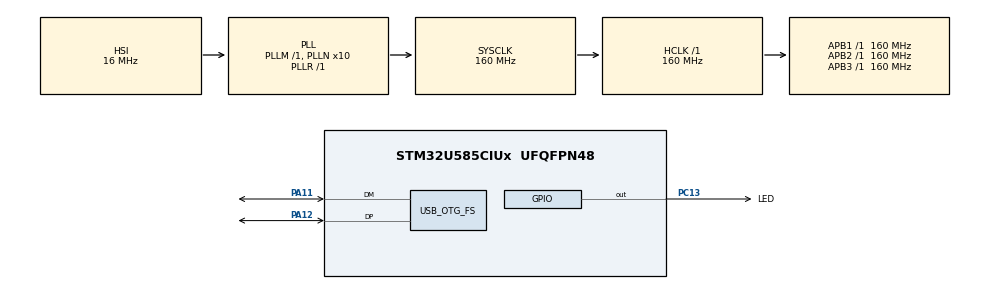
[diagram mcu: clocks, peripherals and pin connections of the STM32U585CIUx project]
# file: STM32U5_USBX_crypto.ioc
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CORTEX_M33_NS.userName=CORTEX_M33
Mcu.Family=STM32U5
Mcu.Name=STM32U585CIUx
Mcu.Package=UFQFPN48
NVIC.OTG_FS_IRQn=true\:7\:0\:true\:false\:true\:false\:true\:true\:true
NVIC.PriorityGroup=NVIC_PRIORITYGROUP_4
NVIC.TIM6_IRQn=true\:15\:0\:false\:false\:true\:false\:false\:true\:true
NVIC.TimeBase=TIM6_IRQn
NVIC.TimeBaseIP=TIM6
PA11.GPIO_Speed=GPIO_SPEED_FREQ_HIGH
PA11.Mode=Device_Only
PA11.Signal=USB_OTG_FS_DM
PA12.GPIO_Speed=GPIO_SPEED_FREQ_HIGH
PA12.Mode=Device_Only
PA12.Signal=USB_OTG_FS_DP
PC13.GPIO_Label=LED
PC13.Signal=GPIO_Output
PH0-OSC_IN\ (PH0).Mode=HSE-External-Oscillator
PH0-OSC_IN\ (PH0).Signal=RCC_OSC_IN
PH1-OSC_OUT\ (PH1).Mode=HSE-External-Oscillator
PH1-OSC_OUT\ (PH1).Signal=RCC_OSC_OUT
ProjectManager.HeapSize=0x200
ProjectManager.StackSize=0x400
ProjectManager.TargetToolchain=STM32CubeIDE
RCC.ADCFreq_Value=16000000
RCC.AHBFreq_Value=160000000
RCC.APB1Freq_Value=160000000
RCC.APB1TimFreq_Value=160000000
RCC.APB2Freq_Value=160000000
RCC.APB2TimFreq_Value=160000000
RCC.APB3Freq_Value=160000000
RCC.CortexFreq_Value=160000000
RCC.EPOD_VALUE=16000000
RCC.HCLKFreq_Value=160000000
RCC.HSE_VALUE=16000000
RCC.HSI48_VALUE=48000000
RCC.HSI_VALUE=16000000
RCC.LSE_VALUE=32768
RCC.LSIDIV_VALUE=32000
RCC.MSIClockRange=RCC_MSIRANGE_0
RCC.MSI_VALUE=48000000
RCC.PLL1R=1
RCC.PLLFRACN=0
RCC.PLLN=10
RCC.PLLSourceVirtual=RCC_PLLSOURCE_HSI
RCC.SYSCLKFreq_VALUE=160000000
RCC.SYSCLKSource=RCC_SYSCLKSOURCE_PLLCLK
RCC.USBFreq_Value=48000000
RCC.VCOOutputFreq_Value=160000000
USBX.BSP.number=1
USBX.Core_System=1
USBX.MAX_POWER_IN_MILLI_AMPER=0
USBX.USBD_CDCACM_EPINCMD_ADDR=2
USBX.USBD_CDCACM_EPIN_ADDR=1
USBX.USBD_SERIAL_NUMBER=CDC_ACM001
USBX.USBX_DEVICE_SYS_SIZE=4*1024
USBX.UX_DEVICE_APP_MEM_POOL_SIZE=8192
USBX.UX_DEVICE_CDC_ACM=1
USBX.UX_DEVICE_CLASS_CDC_ACM_WRITE_AUTO_ZLP=1
USBX.UX_Device_Controller=1
USBX.UX_Device_CoreStack=1
USBX.UX_SLAVE_REQUEST_DATA_MAX_LENGTH=512
USBX0.BSP.STBoard=false
USBX0.BSP.api=Unknown
USBX0.BSP.condition=SEMAOoUSBOoOTGOoFSOoDEVICEOoFOROoUSBX & \!DIE455
USBX0.BSP.instance=USB_OTG_FS
USBX0.BSP.ip=USB_OTG_FS
USBX0.BSP.mode=Device_Only
USBX0.BSP.name=USBDevice
USBX0.BSP.solution=USB_OTG_FS
USB_OTG_FS.VirtualMode=Device_Only
VP_CRC_VS_CRC.Mode=CRC_Activate
VP_ICACHE_VS_ENABLE_ICACHE_MEMORY.Mode=Memoryregions
VP_LPBAMQUEUE_VS_QUEUE.Mode=QUEUEMODE
VP_LPBAM_VS_SIG1.Mode=SmartRun
VP_LPBAM_VS_SIG4.Mode=LPDMA1
VP_MEMORYMAP_VS_MEMORYMAP.Mode=CurAppReg
VP_PKA_VS_PKA.Mode=PKA_Activate
VP_PWR_VS_SECSignals.Mode=Security/Privilege
VP_RNG_VS_RNG.Mode=RNG_Activate
VP_SYS_VS_tim6.Mode=TIM6
VP_THREADX_VS_RTOSJjThreadXJjCoreJjDefault.Mode=Core_Default
VP_USBX_Core_System.Mode=Core_System
VP_USBX_UX\ Device\ CDC\ ACM\ Class_FS.Mode=UX_Device_class_CDC_ACM_FS
VP_USBX_UX\ Device\ Controller_FS.Mode=UX_Device_Controller_FS
VP_USBX_UX\ Device\ CoreStack_FS.Mode=UX_Device_CoreStack_FS
board=custom

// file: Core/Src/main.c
/* USER CODE BEGIN Header */
/**
  ******************************************************************************
  * @file           : main.c
  * @brief          : Main program body
  ******************************************************************************
  * @attention
  *
  * Copyright (c) 2025 STMicroelectronics.
  * All rights reserved.
  *
  * This software is licensed under terms that can be found in the LICENSE file
  * in the root directory of this software component.
  * If no LICENSE file comes with this software, it is provided AS-IS.
  *
  ******************************************************************************
  */
/* USER CODE END Header */
#include "app_threadx.h"
#include "main.h"

CRC_HandleTypeDef hcrc;

PKA_HandleTypeDef hpka;

RNG_HandleTypeDef hrng;

PCD_HandleTypeDef hpcd_USB_OTG_FS;

void SystemClock_Config(void);
static void MX_GPIO_Init(void);
static void MX_ICACHE_Init(void);
static void MX_RNG_Init(void);
static void MX_PKA_Init(void);
static void MX_CRC_Init(void);
void read_uid(uint32_t uid[3]);

/* USER CODE BEGIN 0 */
 void my_debug_marker(int x) {
    //while(1) {

        for (int i = 0; i < x; i++)
           {
               HAL_GPIO_TogglePin(LED_GPIO_Port, LED_Pin);
               for (volatile int j = 0; j < 1000000; j++); // petit délai CPU busy
           }
        for (volatile long int j = 0; j < 10000000; j++);
    //}
}
/* USER CODE END 0 */

int main(void)
{

  /* MCU Configuration--------------------------------------------------------*/

  /* Reset of all peripherals, Initializes the Flash interface and the Systick. */
  HAL_Init();

  /* Configure the system clock */
  SystemClock_Config();

  /* Initialize all configured peripherals */
  MX_GPIO_Init();
  MX_ICACHE_Init();
  MX_RNG_Init();
  MX_PKA_Init();
  MX_CRC_Init();

  MX_ThreadX_Init();

  /* We should never get here as control is now taken by the scheduler */

  /* Infinite loop */
  while (1)
  {

  }
}

void SystemClock_Config(void)
{
  RCC_OscInitTypeDef RCC_OscInitStruct = {0};
  RCC_ClkInitTypeDef RCC_ClkInitStruct = {0};

  /** Configure the main internal regulator output voltage
  */
  if (HAL_PWREx_ControlVoltageScaling(PWR_REGULATOR_VOLTAGE_SCALE1) != HAL_OK)
  {
    Error_Handler();
  }

  /** Initializes the CPU, AHB and APB buses clocks
  */
  RCC_OscInitStruct.OscillatorType = RCC_OSCILLATORTYPE_HSI48|RCC_OSCILLATORTYPE_HSI;
  RCC_OscInitStruct.HSIState = RCC_HSI_ON;
  RCC_OscInitStruct.HSI48State = RCC_HSI48_ON;
  RCC_OscInitStruct.HSICalibrationValue = RCC_HSICALIBRATION_DEFAULT;
  RCC_OscInitStruct.PLL.PLLState = RCC_PLL_ON;
  RCC_OscInitStruct.PLL.PLLSource = RCC_PLLSOURCE_HSI;
  RCC_OscInitStruct.PLL.PLLMBOOST = RCC_PLLMBOOST_DIV1;
  RCC_OscInitStruct.PLL.PLLM = 1;
  RCC_OscInitStruct.PLL.PLLN = 10;
  RCC_OscInitStruct.PLL.PLLP = 2;
  RCC_OscInitStruct.PLL.PLLQ = 2;
  RCC_OscInitStruct.PLL.PLLR = 1;
  RCC_OscInitStruct.PLL.PLLRGE = RCC_PLLVCIRANGE_1;
  RCC_OscInitStruct.PLL.PLLFRACN = 0;
  if (HAL_RCC_OscConfig(&RCC_OscInitStruct) != HAL_OK)
  {
    Error_Handler();
  }

  /** Initializes the CPU, AHB and APB buses clocks
  */
  RCC_ClkInitStruct.ClockType = RCC_CLOCKTYPE_HCLK|RCC_CLOCKTYPE_SYSCLK
                              |RCC_CLOCKTYPE_PCLK1|RCC_CLOCKTYPE_PCLK2
                              |RCC_CLOCKTYPE_PCLK3;
  RCC_ClkInitStruct.SYSCLKSource = RCC_SYSCLKSOURCE_PLLCLK;
  RCC_ClkInitStruct.AHBCLKDivider = RCC_SYSCLK_DIV1;
  RCC_ClkInitStruct.APB1CLKDivider = RCC_HCLK_DIV1;
  RCC_ClkInitStruct.APB2CLKDivider = RCC_HCLK_DIV1;
  RCC_ClkInitStruct.APB3CLKDivider = RCC_HCLK_DIV1;

  if (HAL_RCC_ClockConfig(&RCC_ClkInitStruct, FLASH_LATENCY_4) != HAL_OK)
  {
    Error_Handler();
  }
}

static void MX_CRC_Init(void)
{

  hcrc.Instance = CRC;
  hcrc.Init.DefaultPolynomialUse = DEFAULT_POLYNOMIAL_ENABLE;
  hcrc.Init.DefaultInitValueUse = DEFAULT_INIT_VALUE_ENABLE;
  hcrc.Init.InputDataInversionMode = CRC_INPUTDATA_INVERSION_NONE;
  hcrc.Init.OutputDataInversionMode = CRC_OUTPUTDATA_INVERSION_DISABLE;
  hcrc.InputDataFormat = CRC_INPUTDATA_FORMAT_BYTES;
  if (HAL_CRC_Init(&hcrc) != HAL_OK)
  {
    Error_Handler();
  }

}

static void MX_ICACHE_Init(void)
{

}

static void MX_PKA_Init(void)
{

  hpka.Instance = PKA;
  if (HAL_PKA_Init(&hpka) != HAL_OK)
  {
    Error_Handler();
  }

}

static void MX_RNG_Init(void)
{

  hrng.Instance = RNG;
  hrng.Init.ClockErrorDetection = RNG_CED_ENABLE;
  if (HAL_RNG_Init(&hrng) != HAL_OK)
  {
    Error_Handler();
  }

}

void MX_USB_OTG_FS_PCD_Init(void)
{

  hpcd_USB_OTG_FS.Instance = USB_OTG_FS;
  hpcd_USB_OTG_FS.Init.dev_endpoints = 6;
  hpcd_USB_OTG_FS.Init.speed = PCD_SPEED_FULL;
  hpcd_USB_OTG_FS.Init.phy_itface = PCD_PHY_EMBEDDED;
  hpcd_USB_OTG_FS.Init.Sof_enable = DISABLE;
  hpcd_USB_OTG_FS.Init.low_power_enable = DISABLE;
  hpcd_USB_OTG_FS.Init.lpm_enable = DISABLE;
  hpcd_USB_OTG_FS.Init.battery_charging_enable = DISABLE;
  hpcd_USB_OTG_FS.Init.use_dedicated_ep1 = DISABLE;
  hpcd_USB_OTG_FS.Init.vbus_sensing_enable = DISABLE;
  hpcd_USB_OTG_FS.Init.dma_enable = DISABLE;
  if (HAL_PCD_Init(&hpcd_USB_OTG_FS) != HAL_OK)
  {
    Error_Handler();
  }

}

static void MX_GPIO_Init(void)
{
  GPIO_InitTypeDef GPIO_InitStruct = {0};

  /* GPIO Ports Clock Enable */
  __HAL_RCC_GPIOC_CLK_ENABLE();
  __HAL_RCC_GPIOH_CLK_ENABLE();
  __HAL_RCC_GPIOA_CLK_ENABLE();

  /*Configure GPIO pin Output Level */
  HAL_GPIO_WritePin(LED_GPIO_Port, LED_Pin, GPIO_PIN_RESET);

  /*Configure GPIO pin : LED_Pin */
  GPIO_InitStruct.Pin = LED_Pin;
  GPIO_InitStruct.Mode = GPIO_MODE_OUTPUT_PP;
  GPIO_InitStruct.Pull = GPIO_NOPULL;
  GPIO_InitStruct.Speed = GPIO_SPEED_FREQ_LOW;
  HAL_GPIO_Init(LED_GPIO_Port, &GPIO_InitStruct);

}

void HAL_TIM_PeriodElapsedCallback(TIM_HandleTypeDef *htim)
{
  if (htim->Instance == TIM6)
  {
    HAL_IncTick();
  }
}

void Error_Handler(void)
{
  __disable_irq();
  while (1)
  {
  }
}

void read_uid(uint32_t uid[3])
{
    /* Méthode A : si HAL fournit HAL_GetUIDwX */
#if defined(HAL_GetUIDw0)
    uid[0] = HAL_GetUIDw0();
    uid[1] = HAL_GetUIDw1();
    uid[2] = HAL_GetUIDw2();
#else
    /* Méthode B : lire depuis UID_BASE fourni par le device header */
#if defined(UID_BASE)
    uint32_t *pUID = (uint32_t *)UID_BASE;
    uid[0] = pUID[0]; // mot 0 (LSB)
    uid[1] = pUID[1]; // mot 1
    uid[2] = pUID[2]; // mot 2 (MSB)
#else
    /* Si UID_BASE n'est pas défini, mettre ici l'adresse connue du device (vérifier le RM / header)
       Exemple générique (NE PAS UTILISER sans vérifier) :
       #define UID_BASE 0x1FFF7590UL
       Remplace l'adresse par celle du header de ton MCU si nécessaire.
    */
#error "UID_BASE non défini dans les headers. Vérifie ton fichier stm32u5xx.h ou remplace l'adresse."
#endif
#endif
}
